# IPE3_IPGW_ICONT register map
Vendor: Texas Instruments
Peripheral module from a debugger description file (folder TDA2Px).
Registers are 32-bit, access not given, reset 0x0 unless marked. A register's access mark holds for its fields unless they carry their own. Offsets are as the file gives them; lines under a group give offsets from that group; [hi:lo] are bit positions; {n}, {i} and the like mark numbered series; 'fields as' and 'values as' point back to an identical list; <NAME> marks a mode.

## IPE3_IPGW_ICONT
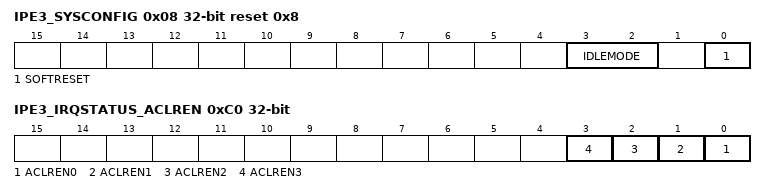
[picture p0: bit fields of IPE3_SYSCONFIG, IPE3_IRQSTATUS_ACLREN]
0x08 IPE3_SYSCONFIG access per field reset 0x8 — Clock management configuration
  [3:2] IDLEMODE rw — Configuration of the local target state management mode. The target can handle read/write transactions as long as it is not in IDLE state. 0: Force-idle mode: Local target IDLE state acknowledges IDLE requests unconditionally (regardless of the IP module internal requirements). 1: No-idle mode: Local target never enters IDLE state. 2: Smart-idle mode: Local target IDLE state eventually acknowledges IDLE requests, depending on the IP module internal requirements. IP module does not generate IRQ- or DMA-request-related wake-up events. 3: Smart-idle wakeup-capable mode: Local target IDLE state eventually acknowledges IDLE requests, depending on the IP module internal requirements. IP module may generate IRQ- or DMA-request-related wake-up events when in IDLE state. Mode is relevant only if the appropriate IP module wake-up output(s) is implemented.
  [0] SOFTRESET rw — Software reset Read 0: Reset done, no pending action Read 1: Reset (software or other) on going Write 0: No action Write 1: Initiate software reset.
0x0C IPE3_IRQ_EOI access per field — End Of Interrupt number specification
  [1:0] LINE_NUMBER rw — Software End Of Interrupt (EOI) control. Write number of interrupt output.
    {v}=EOI_for_interrupt_output_line_#{v} (v=0..3); 0=Reads_always_0_(no_EOI_memory)
{0x14+4i} IPE3_IRQSTATUS_RAW_{i} access per field (i=0..3) — Per-event raw interrupt status vector, line {i}. Raw status is set even if event is not enabled.
  [0] EVENT0 rw — Programmable raw status for event 0 Write 0: No action Read 0: No event pending Read 1: Event pending Write 1: Reserved
{0x30+4i} IPE3_IRQSTATUS_{i} (i=0..3) — Per-event enabled interrupt status vector, line {i}. Enabled status is not set unless event is enabled. Write 1 to clear the status after interrupt has been serviced (raw status gets cleared (even if not enabled).
  [0] EVENT0 — Clearable, enabled status for event 0 Write 0: No action Read 0: No (enabled) event pending Read 1: Event pending Write 1: Clear (raw) event (access RW W1toClr)
{0x4C+4i} IPE3_IRQENABLE_SET_{i} (i=0..2) — Per-event interrupt enable bit vector, line {i}. Write 1 to set (enable interrupt). Readout equal to corresponding _CLR register.
  [0] ENABLE0 — Enable for event 0 Write 0: No action Read 0: Interrupt disabled (masked) Read 1: Interrupt enabled Write 1: Enable interrupt (access RW W1toSet)
0x58 IPE3_IRQENABLE_SET_3 — Per-event interrupt enable bit vector, line 0. Write 1 to set (enable interrupt). Readout equal to corresponding _CLR register.
  fields as IPE3_IRQENABLE_SET_0
{0x68+4i} IPE3_IRQENABLE_CLR_{i} (i=0..2) — Per-event interrupt enable bit vector, line {i}. Write 1 to clear (disable interrupt). Readout equal to corresponding _SET register.
  [0] ENABLE0 — Enable for event 0 Write 0: No action Read 0: Interrupt disabled (masked) Read 1: Interrupt enabled Write 1: Disable interrupt (access RW W1toClr)
0x74 IPE3_IRQENABLE_CLR_3 — Per-event interrupt enable bit vector, line 2. Write 1 to clear (disable interrupt). Readout equal to corresponding _SET register.
  fields as IPE3_IRQENABLE_CLR_0
0xC0 IPE3_IRQSTATUS_ACLREN access per field — Auto clear enable
  [n] ACLREN{n} rw (n=0..3) — Auto clear enable for line {n}
